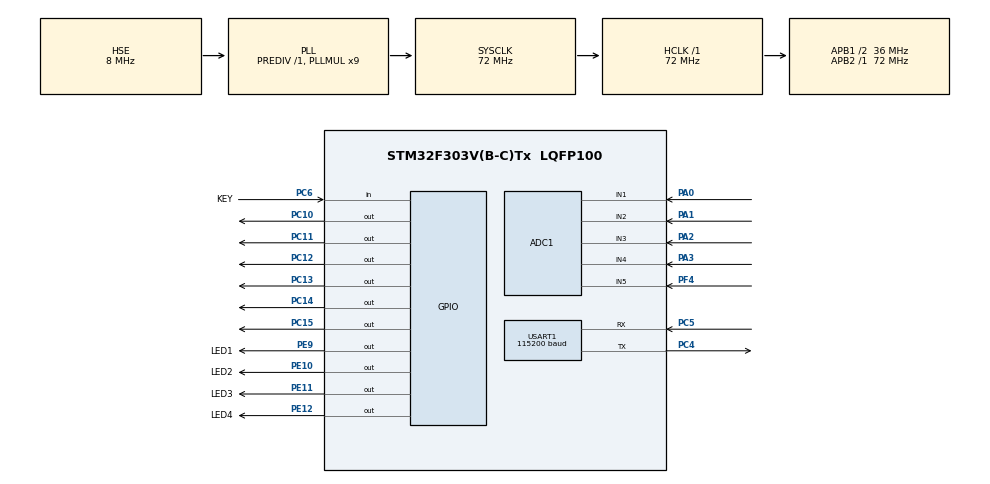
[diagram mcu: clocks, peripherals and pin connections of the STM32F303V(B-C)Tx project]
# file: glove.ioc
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ADC1.Channel-0\#ChannelRegularConversion=ADC_CHANNEL_1
ADC1.Channel-1\#ChannelRegularConversion=ADC_CHANNEL_2
ADC1.Channel-2\#ChannelRegularConversion=ADC_CHANNEL_3
ADC1.Channel-3\#ChannelRegularConversion=ADC_CHANNEL_4
ADC1.Channel-4\#ChannelRegularConversion=ADC_CHANNEL_5
ADC1.ContinuousConvMode=DISABLE
ADC1.DMAContinuousRequests=ENABLE
ADC1.EnableInjectedConversion=DISABLE
ADC1.ExternalTrigConv=ADC_EXTERNALTRIGCONV_T6_TRGO
ADC1.NbrOfConversion=5
ADC1.NbrOfConversionFlag=1
ADC1.Offset-0\#ChannelRegularConversion=0
ADC1.Offset-1\#ChannelRegularConversion=0
ADC1.Offset-2\#ChannelRegularConversion=0
ADC1.Offset-3\#ChannelRegularConversion=0
ADC1.Offset-4\#ChannelRegularConversion=0
ADC1.OffsetNumber-0\#ChannelRegularConversion=ADC_OFFSET_NONE
ADC1.OffsetNumber-1\#ChannelRegularConversion=ADC_OFFSET_NONE
ADC1.OffsetNumber-2\#ChannelRegularConversion=ADC_OFFSET_NONE
ADC1.OffsetNumber-3\#ChannelRegularConversion=ADC_OFFSET_NONE
ADC1.OffsetNumber-4\#ChannelRegularConversion=ADC_OFFSET_NONE
ADC1.Rank-0\#ChannelRegularConversion=1
ADC1.Rank-1\#ChannelRegularConversion=2
ADC1.Rank-2\#ChannelRegularConversion=3
ADC1.Rank-3\#ChannelRegularConversion=4
ADC1.Rank-4\#ChannelRegularConversion=5
ADC1.SamplingTime-0\#ChannelRegularConversion=ADC_SAMPLETIME_1CYCLE_5
ADC1.SamplingTime-1\#ChannelRegularConversion=ADC_SAMPLETIME_1CYCLE_5
ADC1.SamplingTime-2\#ChannelRegularConversion=ADC_SAMPLETIME_1CYCLE_5
ADC1.SamplingTime-3\#ChannelRegularConversion=ADC_SAMPLETIME_1CYCLE_5
ADC1.SamplingTime-4\#ChannelRegularConversion=ADC_SAMPLETIME_1CYCLE_5
ADC1.master=1
Dma.ADC1.0.Direction=DMA_PERIPH_TO_MEMORY
Dma.ADC1.0.Instance=DMA1_Channel1
Dma.ADC1.0.MemDataAlignment=DMA_MDATAALIGN_HALFWORD
Dma.ADC1.0.MemInc=DMA_MINC_ENABLE
Dma.ADC1.0.Mode=DMA_CIRCULAR
Dma.ADC1.0.PeriphDataAlignment=DMA_PDATAALIGN_HALFWORD
Dma.ADC1.0.PeriphInc=DMA_PINC_DISABLE
Dma.ADC1.0.Priority=DMA_PRIORITY_LOW
Dma.Request0=ADC1
Dma.Request1=USART1_RX
Dma.Request2=USART1_TX
Dma.USART1_RX.1.Direction=DMA_PERIPH_TO_MEMORY
Dma.USART1_RX.1.Instance=DMA1_Channel5
Dma.USART1_RX.1.MemDataAlignment=DMA_MDATAALIGN_BYTE
Dma.USART1_RX.1.MemInc=DMA_MINC_ENABLE
Dma.USART1_RX.1.Mode=DMA_NORMAL
Dma.USART1_RX.1.PeriphDataAlignment=DMA_PDATAALIGN_BYTE
Dma.USART1_RX.1.PeriphInc=DMA_PINC_DISABLE
Dma.USART1_RX.1.Priority=DMA_PRIORITY_LOW
Dma.USART1_TX.2.Direction=DMA_MEMORY_TO_PERIPH
Dma.USART1_TX.2.Instance=DMA1_Channel4
Dma.USART1_TX.2.MemDataAlignment=DMA_MDATAALIGN_BYTE
Dma.USART1_TX.2.MemInc=DMA_MINC_ENABLE
Dma.USART1_TX.2.Mode=DMA_NORMAL
Dma.USART1_TX.2.PeriphDataAlignment=DMA_PDATAALIGN_BYTE
Dma.USART1_TX.2.PeriphInc=DMA_PINC_DISABLE
Dma.USART1_TX.2.Priority=DMA_PRIORITY_LOW
Mcu.Family=STM32F3
Mcu.Name=STM32F303V(B-C)Tx
Mcu.Package=LQFP100
NVIC.DMA1_Channel1_IRQn=true\:0\:0\:false\:false\:true\:false\:true
NVIC.DMA1_Channel4_IRQn=true\:0\:0\:false\:false\:true\:false\:true
NVIC.DMA1_Channel5_IRQn=true\:0\:0\:false\:false\:true\:false\:true
NVIC.PriorityGroup=NVIC_PRIORITYGROUP_4
NVIC.TIM6_DAC_IRQn=true\:0\:0\:false\:false\:true\:true\:true
NVIC.USART1_IRQn=true\:0\:0\:false\:false\:true\:true\:true
PA0.Mode=IN1-Single-Ended
PA0.Signal=ADC1_IN1
PA1.Mode=IN2-Single-Ended
PA1.Signal=ADC1_IN2
PA13.Mode=Serial_Wire
PA13.Signal=SYS_JTMS-SWDIO
PA14.Mode=Serial_Wire
PA14.Signal=SYS_JTCK-SWCLK
PA2.Mode=IN3-Single-Ended
PA2.Signal=ADC1_IN3
PA3.Mode=IN4-Single-Ended
PA3.Signal=ADC1_IN4
PC10.Signal=GPIO_Output
PC11.PinState=GPIO_PIN_SET
PC11.Signal=GPIO_Output
PC12.Signal=GPIO_Output
PC13.Signal=GPIO_Output
PC14-OSC32_IN.Signal=GPIO_Output
PC15-OSC32_OUT.Signal=GPIO_Output
PC4.Mode=Asynchronous
PC4.Signal=USART1_TX
PC5.Mode=Asynchronous
PC5.Signal=USART1_RX
PC6.GPIO_Label=KEY
PC6.GPIO_PuPd=GPIO_PULLUP
PC6.Signal=GPIO_Input
PE10.GPIO_Label=LED2
PE10.Signal=GPIO_Output
PE11.GPIO_Label=LED3
PE11.Signal=GPIO_Output
PE12.GPIO_Label=LED4
PE12.Signal=GPIO_Output
PE9.GPIO_Label=LED1
PE9.GPIO_PuPd=GPIO_NOPULL
PE9.PinState=GPIO_PIN_RESET
PE9.Signal=GPIO_Output
PF0-OSC_IN.Mode=HSE-External-Oscillator
PF0-OSC_IN.Signal=RCC_OSC_IN
PF1-OSC_OUT.Mode=HSE-External-Oscillator
PF1-OSC_OUT.Signal=RCC_OSC_OUT
PF4.Mode=IN5-Single-Ended
PF4.Signal=ADC1_IN5
ProjectManager.HeapSize=0x200
ProjectManager.StackSize=0x400
ProjectManager.TargetToolchain=Makefile
RCC.AHBFreq_Value=72000000
RCC.APB1CLKDivider=RCC_HCLK_DIV2
RCC.APB1Freq_Value=36000000
RCC.APB1TimFreq_Value=72000000
RCC.APB2Freq_Value=72000000
RCC.APB2TimFreq_Value=72000000
RCC.CortexFreq_Value=72000000
RCC.HCLKFreq_Value=72000000
RCC.HSE_VALUE=8000000
RCC.HSI_VALUE=8000000
RCC.LSE_VALUE=32768
RCC.PLLMUL=RCC_PLL_MUL9
RCC.PLLSourceVirtual=RCC_PLLSOURCE_HSE
RCC.SYSCLKFreq_VALUE=72000000
RCC.SYSCLKSourceVirtual=RCC_SYSCLKSOURCE_PLLCLK
RCC.USBFreq_Value=72000000
TIM6.AutoReloadPreload=TIM_AUTORELOAD_PRELOAD_ENABLE
TIM6.Period=1000
TIM6.Prescaler=72
TIM6.TIM_MasterOutputTrigger=TIM_TRGO_UPDATE
USART1.BaudRate=115200
USART1.VirtualMode-Asynchronous=VM_ASYNC
USART1.WordLength=WORDLENGTH_8B
VP_TIM6_VS_ClockSourceINT.Mode=Enable_Timer
board=custom

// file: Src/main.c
/* USER CODE BEGIN Header */
/**
  ******************************************************************************
  * @file           : main.c
  * @brief          : Main program body
  ******************************************************************************
  * @attention
  *
  * <h2><center>&copy; Copyright (c) 2020 STMicroelectronics.
  * All rights reserved.</center></h2>
  *
  * This software component is licensed by ST under BSD 3-Clause license,
  * the "License"; You may not use this file except in compliance with the
  * License. You may obtain a copy of the License at:
  *                        opensource.org/licenses/BSD-3-Clause
  *
  ******************************************************************************
  */
/* USER CODE END Header */

#include "main.h"
#include "adc.h"
#include "dma.h"
#include "tim.h"
#include "usart.h"
#include "gpio.h"

void SystemClock_Config(void);
/* USER CODE BEGIN PFP */
void user_loop();
void user_setup();
/* USER CODE END PFP */

int main(void)
{

  /* MCU Configuration--------------------------------------------------------*/

  /* Reset of all peripherals, Initializes the Flash interface and the Systick. */
  HAL_Init();

  /* Configure the system clock */
  SystemClock_Config();

  /* Initialize all configured peripherals */
  MX_GPIO_Init();
  MX_DMA_Init();
  MX_ADC1_Init();
  MX_USART1_UART_Init();
  MX_TIM6_Init();
  /* USER CODE BEGIN 2 */

  __HAL_UART_CLEAR_FLAG(&huart1, UART_FLAG_TC);
  // __HAL_UART_CLEAR_FLAG(&huart3, UART_FLAG_TC);

  __HAL_UART_ENABLE_IT(&huart1, UART_IT_IDLE);
  // __HAL_UART_ENABLE_IT(&huart3, UART_IT_IDLE);

  HAL_UART_Receive_DMA(&huart1, xtUart1.RxBuf, RECEIVELEN);
  // HAL_UART_Receive_DMA(&huart3, xtUart3.RxBuf, RECEIVELEN);

  user_setup();

  /* USER CODE END 2 */

  /* Infinite loop */
  /* USER CODE BEGIN WHILE */
  while (1)
  {
    user_loop();
    /* USER CODE END WHILE */

  }
}

void SystemClock_Config(void)
{
  RCC_OscInitTypeDef RCC_OscInitStruct = {0};
  RCC_ClkInitTypeDef RCC_ClkInitStruct = {0};
  RCC_PeriphCLKInitTypeDef PeriphClkInit = {0};

  /** Initializes the CPU, AHB and APB busses clocks
  */
  RCC_OscInitStruct.OscillatorType = RCC_OSCILLATORTYPE_HSE;
  RCC_OscInitStruct.HSEState = RCC_HSE_ON;
  RCC_OscInitStruct.HSEPredivValue = RCC_HSE_PREDIV_DIV1;
  RCC_OscInitStruct.HSIState = RCC_HSI_ON;
  RCC_OscInitStruct.PLL.PLLState = RCC_PLL_ON;
  RCC_OscInitStruct.PLL.PLLSource = RCC_PLLSOURCE_HSE;
  RCC_OscInitStruct.PLL.PLLMUL = RCC_PLL_MUL9;
  if (HAL_RCC_OscConfig(&RCC_OscInitStruct) != HAL_OK)
  {
    Error_Handler();
  }
  /** Initializes the CPU, AHB and APB busses clocks
  */
  RCC_ClkInitStruct.ClockType = RCC_CLOCKTYPE_HCLK|RCC_CLOCKTYPE_SYSCLK
                              |RCC_CLOCKTYPE_PCLK1|RCC_CLOCKTYPE_PCLK2;
  RCC_ClkInitStruct.SYSCLKSource = RCC_SYSCLKSOURCE_PLLCLK;
  RCC_ClkInitStruct.AHBCLKDivider = RCC_SYSCLK_DIV1;
  RCC_ClkInitStruct.APB1CLKDivider = RCC_HCLK_DIV2;
  RCC_ClkInitStruct.APB2CLKDivider = RCC_HCLK_DIV1;

  if (HAL_RCC_ClockConfig(&RCC_ClkInitStruct, FLASH_LATENCY_2) != HAL_OK)
  {
    Error_Handler();
  }
  PeriphClkInit.PeriphClockSelection = RCC_PERIPHCLK_USART1|RCC_PERIPHCLK_ADC12;
  PeriphClkInit.Usart1ClockSelection = RCC_USART1CLKSOURCE_PCLK2;
  PeriphClkInit.Adc12ClockSelection = RCC_ADC12PLLCLK_DIV1;
  if (HAL_RCCEx_PeriphCLKConfig(&PeriphClkInit) != HAL_OK)
  {
    Error_Handler();
  }
}

void Error_Handler(void)
{
}

/************************ (C) COPYRIGHT STMicroelectronics *****END OF FILE****/
